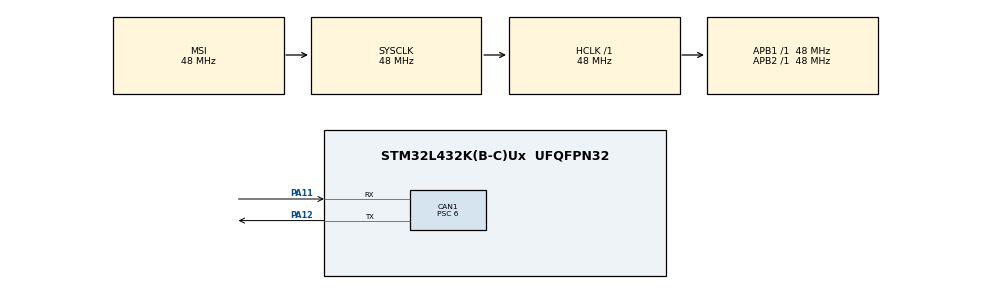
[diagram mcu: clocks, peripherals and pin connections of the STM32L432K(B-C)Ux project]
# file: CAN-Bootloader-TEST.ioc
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CAN1.BS1=CAN_BS1_13TQ
CAN1.BS2=CAN_BS2_2TQ
CAN1.CalculateBaudRate=500000
CAN1.CalculateTimeBit=2000
CAN1.CalculateTimeQuantum=125.0
CAN1.Prescaler=6
Mcu.Family=STM32L4
Mcu.Name=STM32L432K(B-C)Ux
Mcu.Package=UFQFPN32
NVIC.PriorityGroup=NVIC_PRIORITYGROUP_4
PA11.Mode=CAN_Activate
PA11.Signal=CAN1_RX
PA12.Mode=CAN_Activate
PA12.Signal=CAN1_TX
ProjectManager.HeapSize=0x200
ProjectManager.StackSize=0x400
ProjectManager.TargetToolchain=Makefile
RCC.ADCFreq_Value=64000000
RCC.AHBFreq_Value=48000000
RCC.APB1Freq_Value=48000000
RCC.APB1TimFreq_Value=48000000
RCC.APB2Freq_Value=48000000
RCC.APB2TimFreq_Value=48000000
RCC.CortexFreq_Value=48000000
RCC.HCLKFreq_Value=48000000
RCC.HSE_VALUE=8000000
RCC.HSI48_VALUE=48000000
RCC.HSI_VALUE=16000000
RCC.LSE_VALUE=32768
RCC.MSIClockRange=RCC_MSIRANGE_11
RCC.MSI_VALUE=48000000
RCC.PLLM=3
RCC.SYSCLKFreq_VALUE=48000000
RCC.USBFreq_Value=64000000
RCC.VCOOutputFreq_Value=128000000
board=custom

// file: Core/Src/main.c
/* USER CODE BEGIN Header */
/**
  ******************************************************************************
  * @file           : main.c
  * @brief          : Main program body
  ******************************************************************************
  * @attention
  *
  * Copyright (c) 2025 STMicroelectronics.
  * All rights reserved.
  *
  * This software is licensed under terms that can be found in the LICENSE file
  * in the root directory of this software component.
  * If no LICENSE file comes with this software, it is provided AS-IS.
  *
  ******************************************************************************
  */
/* USER CODE END Header */
#include "main.h"

/* USER CODE BEGIN Includes */
#include "bootloader.h"
/* USER CODE END Includes */

CAN_HandleTypeDef hcan1;

void SystemClock_Config(void);
static void MX_GPIO_Init(void);
static void MX_CAN1_Init(void);

int main(void)
{

  /* MCU Configuration--------------------------------------------------------*/

  /* Reset of all peripherals, Initializes the Flash interface and the Systick. */
  HAL_Init();

  /* Configure the system clock */
  SystemClock_Config();

  /* Initialize all configured peripherals */
  MX_GPIO_Init();
  MX_CAN1_Init();
  /* USER CODE BEGIN 2 */

  /* Initialize bootloader */
  Bootloader_Init(&hcan1);

  /* Run bootloader main loop */
  Bootloader_Main();

  /* USER CODE END 2 */

  /* Infinite loop */
  while (1)
  {

  }
}

void SystemClock_Config(void)
{
  RCC_OscInitTypeDef RCC_OscInitStruct = {0};
  RCC_ClkInitTypeDef RCC_ClkInitStruct = {0};

  /** Configure the main internal regulator output voltage
  */
  if (HAL_PWREx_ControlVoltageScaling(PWR_REGULATOR_VOLTAGE_SCALE1) != HAL_OK)
  {
    Error_Handler();
  }

  /** Initializes the RCC Oscillators according to the specified parameters
  * in the RCC_OscInitTypeDef structure.
  */
  RCC_OscInitStruct.OscillatorType = RCC_OSCILLATORTYPE_MSI;
  RCC_OscInitStruct.MSIState = RCC_MSI_ON;
  RCC_OscInitStruct.MSICalibrationValue = 0;
  RCC_OscInitStruct.MSIClockRange = RCC_MSIRANGE_11;
  RCC_OscInitStruct.PLL.PLLState = RCC_PLL_NONE;
  if (HAL_RCC_OscConfig(&RCC_OscInitStruct) != HAL_OK)
  {
    Error_Handler();
  }

  /** Initializes the CPU, AHB and APB buses clocks
  */
  RCC_ClkInitStruct.ClockType = RCC_CLOCKTYPE_HCLK|RCC_CLOCKTYPE_SYSCLK
                              |RCC_CLOCKTYPE_PCLK1|RCC_CLOCKTYPE_PCLK2;
  RCC_ClkInitStruct.SYSCLKSource = RCC_SYSCLKSOURCE_MSI;
  RCC_ClkInitStruct.AHBCLKDivider = RCC_SYSCLK_DIV1;
  RCC_ClkInitStruct.APB1CLKDivider = RCC_HCLK_DIV1;
  RCC_ClkInitStruct.APB2CLKDivider = RCC_HCLK_DIV1;

  if (HAL_RCC_ClockConfig(&RCC_ClkInitStruct, FLASH_LATENCY_2) != HAL_OK)
  {
    Error_Handler();
  }
}

static void MX_CAN1_Init(void)
{

  hcan1.Instance = CAN1;
  hcan1.Init.Prescaler = 6;
  hcan1.Init.Mode = CAN_MODE_NORMAL;
  hcan1.Init.SyncJumpWidth = CAN_SJW_1TQ;
  hcan1.Init.TimeSeg1 = CAN_BS1_13TQ;
  hcan1.Init.TimeSeg2 = CAN_BS2_2TQ;
  hcan1.Init.TimeTriggeredMode = DISABLE;
  hcan1.Init.AutoBusOff = ENABLE;
  hcan1.Init.AutoWakeUp = DISABLE;
  hcan1.Init.AutoRetransmission = ENABLE;
  hcan1.Init.ReceiveFifoLocked = ENABLE;
  hcan1.Init.TransmitFifoPriority = DISABLE;
  if (HAL_CAN_Init(&hcan1) != HAL_OK)
  {
    Error_Handler();
  }

}

static void MX_GPIO_Init(void)
{
  GPIO_InitTypeDef GPIO_InitStruct = {0};

  /* GPIO Ports Clock Enable */
  __HAL_RCC_GPIOA_CLK_ENABLE();
  __HAL_RCC_GPIOB_CLK_ENABLE();

  /* USER CODE BEGIN MX_GPIO_Init_2 */
  /* Enable GPIOB clock for onboard LED at PB3 */
  __HAL_RCC_GPIOB_CLK_ENABLE();

  /* Initialize LED pin (PB3) */
  GPIO_InitStruct.Pin = LED_PIN;
  GPIO_InitStruct.Mode = GPIO_MODE_OUTPUT_PP;
  GPIO_InitStruct.Pull = GPIO_NOPULL;
  GPIO_InitStruct.Speed = GPIO_SPEED_FREQ_LOW;
  HAL_GPIO_Init(LED_PORT, &GPIO_InitStruct);
  /* USER CODE END MX_GPIO_Init_2 */
}

void Error_Handler(void)
{
  __disable_irq();
  while (1)
  {
  }
}
